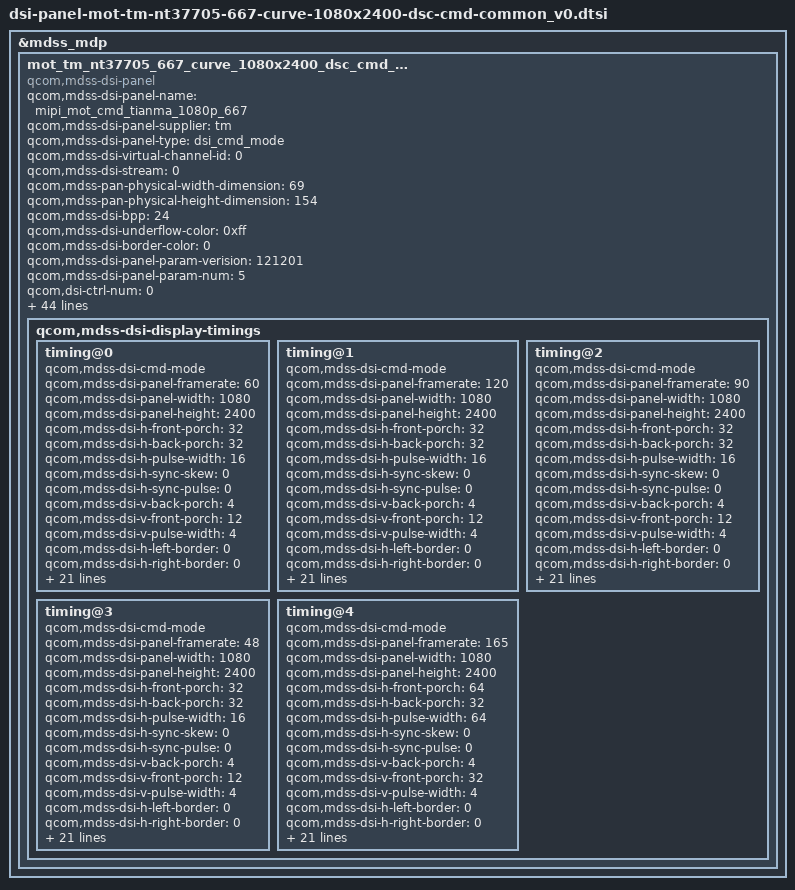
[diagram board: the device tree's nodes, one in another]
/* Copyright (c) 2019-2020, The Linux Foundation. All rights reserved.
 *
 * This program is free software; you can redistribute it and/or modify
 * it under the terms of the GNU General Public License version 2 and
 * only version 2 as published by the Free Software Foundation.
 *
 * This program is distributed in the hope that it will be useful,
 * but WITHOUT ANY WARRANTY; without even the implied warranty of
 * MERCHANTABILITY or FITNESS FOR A PARTICULAR PURPOSE.  See the
 * GNU General Public License for more details.
 */
#include "dsi-panel-mot-tm-nt37705-667-curve-1080x2400-dsc-cmd-common_v0_lhbm.dtsi"
&mdss_mdp {
mot_tm_nt37705_667_curve_1080x2400_dsc_cmd_v0: qcom,mdss_dsi_mot_tm_nt37705_667_curve_1080x2400_dsc_cmd_v0 {
compatible = "qcom,mdss-dsi-panel";
qcom,mdss-dsi-panel-name = "mipi_mot_cmd_tianma_1080p_667";
qcom,mdss-dsi-panel-supplier = "tm";
qcom,mdss-dsi-panel-type = "dsi_cmd_mode";
qcom,mdss-dsi-virtual-channel-id = <0>;
qcom,mdss-dsi-stream = <0>;
qcom,mdss-pan-physical-width-dimension = <69>;
qcom,mdss-pan-physical-height-dimension = <154>;
qcom,mdss-dsi-bpp = <24>;
qcom,mdss-dsi-underflow-color = <0xff>;
qcom,mdss-dsi-border-color = <0>;
qcom,mdss-dsi-panel-param-verision = <121201>;
qcom,mdss-dsi-panel-param-num = <5>;

qcom,dsi-ctrl-num = <0>;
qcom,dsi-phy-num = <0>;

qcom,mdss-dsi-traffic-mode = "burst_mode";
qcom,mdss-dsi-bllp-eof-power-mode;
qcom,mdss-dsi-bllp-power-mode;
qcom,mdss-dsi-lane-0-state;
qcom,mdss-dsi-lane-1-state;
qcom,mdss-dsi-lane-2-state;
qcom,mdss-dsi-lane-3-state;

qcom,mdss-dsi-dma-trigger = "trigger_sw";
qcom,mdss-dsi-mdp-trigger = "none";
qcom,mdss-dsi-reset-sequence = <0 12>, <1 1>, <0 1>, <1 13>;
qcom,mdss-dsi-lp11-init;
qcom,mdss-dsi-tx-eot-append;
qcom,mdss-dsi-te-pin-select = <1>;
qcom,mdss-dsi-te-dcs-command = <1>;
qcom,mdss-dsi-te-using-te-pin;

//qcom,bklt-dcs-2bytes-enabled;
qcom,mdss-dsi-bl-min-level = <4>;
qcom,mdss-dsi-bl-max-level = <14056>;
qcom,mdss-dsi-bl-pmic-control-type = "bl_ctrl_dcs";

qcom,mdss-dsi-panel-hdr-enabled;
qcom,mdss-dsi-panel-hdr-color-primaries = <14500 15500 32000
	        17000 15500 30000 8000 3000>;
qcom,mdss-dsi-panel-peak-brightness = <4200000>;

qcom,mdss-dsi-panel-blackness-level = <3230>;

qcom,mdss-dsi-dc-off-command = [
		39 00 00 00 00 00 06 F0 55 AA 52 08 00
		39 00 00 40 00 00 02 B2 01
		39 00 00 40 00 00 02 6F 02
		39 00 00 40 00 00 03 B2 3F 00
		39 00 00 40 00 00 1F B3 00 01 01 59 01 59 01 EA 01 EA 02 95 02 95 03 4D 03 4D 04 25 04 25 05 3C 05 3C 06 8A 06 8A
		39 00 00 40 00 00 02 6F 1E
		39 00 00 40 00 00 0F B3 06 8F 06 8F 09 80 09 80 0D BA 0D BA 0F FF
		39 00 00 40 00 00 02 6F 11
		39 00 00 40 00 00 04 B2 05 05 04
		39 00 00 40 00 00 06 F0 55 AA 52 08 01
		39 00 00 40 00 00 02 6F 05
		39 00 00 40 00 00 18 BB 44 44 44 44 44 44 44 44 44 44 44 44 44 44 44 44 40 40 40 40 40 40 4A
		39 00 00 00 00 00 06 F0 55 AA 52 08 02
		39 00 00 00 00 00 02 CC 10
		];

qcom,mdss-dsi-dc-off-command-state = "dsi_hs_mode";
qcom,mdss-dsi-dc-on-command = [
		39 00 00 00 00 00 06 F0 55 AA 52 08 00
		39 00 00 40 00 00 02 B2 80
		39 00 00 40 00 00 02 6F 02
		39 00 00 40 00 00 03 B2 FF 8F
		39 00 00 40 00 00 1F B3 00 00 00 00 00 00 00 00 00 00 00 00 00 00 00 00 00 00 00 00 00 00 00 00 00 00 00 00 00 00
		39 00 00 40 00 00 02 6F 1E
		39 00 00 40 00 00 0F B3 06 8F 06 8F 09 80 09 80 0D BA 0D BA 0F FF
		39 00 00 40 00 00 02 6F 11
		39 00 00 40 00 00 04 B2 00 00 00
		39 00 00 40 00 00 06 F0 55 AA 52 08 01
		39 00 00 40 00 00 02 6F 05
		39 00 00 40 00 00 18 BB 44 44 44 44 44 44 44 44 44 44 44 44 44 44 44 42 40 40 40 40 40 40 4A
		39 00 00 00 00 00 06 F0 55 AA 52 08 02
		39 00 00 00 00 00 02 CC 10
		];
qcom,mdss-dsi-dc-on-command-state = "dsi_hs_mode";

qcom,mdss-dsi-hbm-on-command = [
		39 00 00 00 00 00 03 51 3F FC
		39 00 00 00 00 00 02 87 00];

qcom,mdss-dsi-hbm-off-command = [
		39 00 00 00 00 00 02 87 00];

qcom,mdss-dsi-hbm-fod;
qcom,mdss-dsi-hbm-fod-on-command = [
		39 00 00 40 00 00 02 6F 01
		39 00 00 40 00 00 03 87 0F FF
		39 00 00 00 00 00 02 87 25];

qcom,mdss-dsi-panel-local-hbm-enabled;
qcom,mdss-dsi-panel-local-hbm-alpha-register = <0x87>;
qcom,mdss-dsi-panel-local-hbm-alpha-size = <4096>;

qcom,mdss-dsi-display-timings {
	timing@0{
		qcom,mdss-dsi-cmd-mode;
		qcom,mdss-dsi-panel-framerate = <60>;
		qcom,mdss-dsi-panel-width = <1080>;
		qcom,mdss-dsi-panel-height = <2400>;
		qcom,mdss-dsi-h-front-porch = <32>;
		qcom,mdss-dsi-h-back-porch = <32>;
		qcom,mdss-dsi-h-pulse-width = <16>;
		qcom,mdss-dsi-h-sync-skew = <0>;
		qcom,mdss-dsi-h-sync-pulse = <0>;
		qcom,mdss-dsi-v-back-porch = <4>;
		qcom,mdss-dsi-v-front-porch = <12>;
		qcom,mdss-dsi-v-pulse-width = <4>;
		qcom,mdss-dsi-h-left-border = <0>;
		qcom,mdss-dsi-h-right-border = <0>;
		qcom,mdss-dsi-v-top-border = <0>;
		qcom,mdss-dsi-v-bottom-border = <0>;
		qcom,mdss-mdp-transfer-time-us = <5500>;
		qcom,mdss-dsi-timing-switch-command = [
			15 01 00 00 10 00 02 2F 02 //03:48Hz 02:60Hz 01:90Hz 00:120Hz 04:165HZ
		];
		qcom,mdss-dsi-on-command = [
                        39 01 00 00 00 00 06 F0 55 AA 52 08 01
     			39 01 00 00 00 00 02 6F 05
			39 01 00 00 00 00 05 C5 15 15 15 DD
			39 01 00 00 00 00 02 6F 02
			39 01 00 00 00 00 03 C7 00 00
			39 01 00 00 00 00 06 F0 55 AA 52 08 07
			39 01 00 00 00 00 16 C4 36 00 05 F1 02 11 07 02 00 01 97 9C 3F FD FD 20 00 00 02 04 F1
			39 01 00 00 00 00 05 FF AA 55 A5 80
			39 01 00 00 00 00 02 6F 1A
			39 01 00 00 00 00 02 F4 55
			39 01 00 00 00 00 02 6F 15
			39 01 00 00 00 00 03 F8 01 5C
			39 01 00 00 00 00 02 6F 31
			39 01 00 00 00 00 03 F8 01 07
			39 01 00 00 00 00 02 6F 01
			39 01 00 00 00 00 02 1F 06
			39 01 00 00 00 00 02 6F 0F
			39 01 00 00 00 00 02 FC 00
			39 01 00 00 00 00 02 6F 09
			39 01 00 00 00 00 03 FC FC F0
			39 01 00 00 00 00 05 FF AA 55 A5 81
			39 01 00 00 00 00 02 6F 0E
			39 01 00 00 00 00 02 F5 00
			39 01 00 00 00 00 02 6F 19
			39 01 00 00 00 00 02 FB 00
			39 01 00 00 00 00 02 6F 05
			39 01 00 00 00 00 02 FE 3C
			39 01 00 00 00 00 02 6F 1E
			39 01 00 00 00 00 02 FB 0F
			39 01 00 00 00 00 05 FF AA 55 A5 83
			39 01 00 00 00 00 02 6F 12
			39 01 00 00 00 00 02 FE 41
			39 01 00 00 00 00 02 17 10
			39 01 00 00 00 00 02 26 00
			39 01 00 00 00 00 05 2A 00 00 04 37
			39 01 00 00 00 00 05 2B 00 00 09 5F
			39 01 00 00 00 00 02 2F 02
			39 01 00 00 00 00 02 35 00
			39 01 00 00 00 00 03 51 00 00
			39 01 00 00 00 00 02 53 20
			39 01 00 00 00 00 0A 88 01 02 1C 08 5E 00 00 00 00
			39 01 00 00 00 00 02 6F 01
			39 01 00 00 00 00 03 87 0F FF
			39 01 00 00 00 00 03 90 03 03
			39 01 00 00 00 00 13 91 AB 28 00 0C D2 00 02 25 01 14 00 07 09 75 08 7A 10 F0
			39 01 00 00 00 00 03 C7 00 00
			39 01 00 00 00 00 02 26 00
			39 01 00 00 00 00 02 1F 40
			39 01 00 00 00 00 05 FF AA 55 A5 81
                        39 01 00 00 00 00 02 6F 1E
                        39 01 00 00 00 00 02 FB 0F
                        39 01 00 00 00 00 06 F0 55 AA 52 08 00
                        39 01 00 00 00 00 03 B2 01 60
			05 01 00 00 64 00 01 11
			05 01 00 00 00 00 01 29];	/* display on */
		qcom,mdss-dsi-off-command = [
			05 01 00 00 00 00 01 28		/* display_off */
			05 01 00 00 78 00 01 10];	/* enter sleep mode */

		qcom,mdss-dsi-on-command-state = "dsi_lp_mode";
		qcom,mdss-dsi-off-command-state = "dsi_lp_mode";
		qcom,mdss-dsi-timing-switch-command-state =
			"dsi_lp_mode";
		qcom,compression-mode = "dsc";
		/* Why QCOM doesn't use this, even it used 2 encoder
		 * as for that dsi_sw43404_amoled_cmd, for ex */
		/* qcom,mdss-dsc-encoders = <2>; */
		qcom,mdss-dsc-version = <0x11>;
		qcom,mdss-dsc-slice-height = <12>;
		qcom,mdss-dsc-slice-width = <540>;
		qcom,mdss-dsc-slice-per-pkt = <1>;
		qcom,mdss-dsc-bit-per-component = <10>;
		qcom,mdss-dsc-bit-per-pixel = <8>;
		qcom,mdss-dsc-block-prediction-enable;
	};

	timing@1{
		qcom,mdss-dsi-cmd-mode;
		qcom,mdss-dsi-panel-framerate = <120>;
		qcom,mdss-dsi-panel-width = <1080>;
		qcom,mdss-dsi-panel-height = <2400>;
		qcom,mdss-dsi-h-front-porch = <32>;
		qcom,mdss-dsi-h-back-porch = <32>;
		qcom,mdss-dsi-h-pulse-width = <16>;
		qcom,mdss-dsi-h-sync-skew = <0>;
		qcom,mdss-dsi-h-sync-pulse = <0>;
		qcom,mdss-dsi-v-back-porch = <4>;
		qcom,mdss-dsi-v-front-porch = <12>;
		qcom,mdss-dsi-v-pulse-width = <4>;
		qcom,mdss-dsi-h-left-border = <0>;
		qcom,mdss-dsi-h-right-border = <0>;
		qcom,mdss-dsi-v-top-border = <0>;
		qcom,mdss-dsi-v-bottom-border = <0>;
		qcom,mdss-mdp-transfer-time-us = <5500>;
		qcom,mdss-dsi-timing-switch-command = [
			15 01 00 00 10 00 02 2F 00 //03:48Hz 02:60Hz 01:90Hz 00:120Hz 04:165HZ
		];
		qcom,mdss-dsi-on-command = [
                        39 01 00 00 00 00 06 F0 55 AA 52 08 01
     			39 01 00 00 00 00 02 6F 05
			39 01 00 00 00 00 05 C5 15 15 15 DD
			39 01 00 00 00 00 02 6F 02
			39 01 00 00 00 00 03 C7 00 00
			39 01 00 00 00 00 06 F0 55 AA 52 08 07
			39 01 00 00 00 00 16 C4 36 00 05 F1 02 11 07 02 00 01 97 9C 3F FD FD 20 00 00 02 04 F1
			39 01 00 00 00 00 05 FF AA 55 A5 80
			39 01 00 00 00 00 02 6F 1A
			39 01 00 00 00 00 02 F4 55
			39 01 00 00 00 00 02 6F 15
			39 01 00 00 00 00 03 F8 01 5C
			39 01 00 00 00 00 02 6F 31
			39 01 00 00 00 00 03 F8 01 07
			39 01 00 00 00 00 02 6F 01
			39 01 00 00 00 00 02 1F 06
			39 01 00 00 00 00 02 6F 0F
			39 01 00 00 00 00 02 FC 00
			39 01 00 00 00 00 02 6F 09
			39 01 00 00 00 00 03 FC FC F0
			39 01 00 00 00 00 05 FF AA 55 A5 81
			39 01 00 00 00 00 02 6F 0E
			39 01 00 00 00 00 02 F5 00
			39 01 00 00 00 00 02 6F 19
			39 01 00 00 00 00 02 FB 00
			39 01 00 00 00 00 02 6F 05
			39 01 00 00 00 00 02 FE 3C
			39 01 00 00 00 00 02 6F 1E
			39 01 00 00 00 00 02 FB 0F
			39 01 00 00 00 00 05 FF AA 55 A5 83
			39 01 00 00 00 00 02 6F 12
			39 01 00 00 00 00 02 FE 41
			39 01 00 00 00 00 02 17 10
			39 01 00 00 00 00 02 26 00
			39 01 00 00 00 00 05 2A 00 00 04 37
			39 01 00 00 00 00 05 2B 00 00 09 5F
			39 01 00 00 00 00 02 2F 00
			39 01 00 00 00 00 02 35 00
			39 01 00 00 00 00 03 51 00 00
			39 01 00 00 00 00 02 53 20
			39 01 00 00 00 00 0A 88 01 02 1C 08 5E 00 00 00 00
			39 01 00 00 00 00 02 6F 01
			39 01 00 00 00 00 03 87 0F FF
			39 01 00 00 00 00 03 90 03 03
			39 01 00 00 00 00 13 91 AB 28 00 0C D2 00 02 25 01 14 00 07 09 75 08 7A 10 F0
			39 01 00 00 00 00 03 C7 00 00
			39 01 00 00 00 00 02 26 00
			39 01 00 00 00 00 02 1F 40
			39 01 00 00 00 00 05 FF AA 55 A5 81
                        39 01 00 00 00 00 02 6F 1E
                        39 01 00 00 00 00 02 FB 0F
                        39 01 00 00 00 00 06 F0 55 AA 52 08 00
                        39 01 00 00 00 00 03 B2 01 60
			05 01 00 00 64 00 01 11
			05 01 00 00 00 00 01 29];	/* display on */
		qcom,mdss-dsi-off-command = [
			05 01 00 00 00 00 01 28		/* display_off */
			05 01 00 00 78 00 01 10];	/* enter sleep mode */

		qcom,mdss-dsi-on-command-state = "dsi_lp_mode";
		qcom,mdss-dsi-off-command-state = "dsi_lp_mode";
		qcom,mdss-dsi-timing-switch-command-state =
			"dsi_lp_mode";
		qcom,compression-mode = "dsc";
		/* Why QCOM doesn't use this, even it used 2 encoder
		 * as for that dsi_sw43404_amoled_cmd, for ex */
		/* qcom,mdss-dsc-encoders = <2>; */
		qcom,mdss-dsc-version = <0x11>;
		qcom,mdss-dsc-slice-height = <12>;
		qcom,mdss-dsc-slice-width = <540>;
		qcom,mdss-dsc-slice-per-pkt = <1>;
		qcom,mdss-dsc-bit-per-component = <10>;
		qcom,mdss-dsc-bit-per-pixel = <8>;
		qcom,mdss-dsc-block-prediction-enable;
	};
	timing@2{
		qcom,mdss-dsi-cmd-mode;
		qcom,mdss-dsi-panel-framerate = <90>;
		qcom,mdss-dsi-panel-width = <1080>;
		qcom,mdss-dsi-panel-height = <2400>;
		qcom,mdss-dsi-h-front-porch = <32>;
		qcom,mdss-dsi-h-back-porch = <32>;
		qcom,mdss-dsi-h-pulse-width = <16>;
		qcom,mdss-dsi-h-sync-skew = <0>;
		qcom,mdss-dsi-h-sync-pulse = <0>;
		qcom,mdss-dsi-v-back-porch = <4>;
		qcom,mdss-dsi-v-front-porch = <12>;
		qcom,mdss-dsi-v-pulse-width = <4>;
		qcom,mdss-dsi-h-left-border = <0>;
		qcom,mdss-dsi-h-right-border = <0>;
		qcom,mdss-dsi-v-top-border = <0>;
		qcom,mdss-dsi-v-bottom-border = <0>;
		qcom,mdss-mdp-transfer-time-us = <5500>;
		qcom,mdss-dsi-timing-switch-command = [
			15 01 00 00 10 00 02 2F 01 //03:48Hz 02:60Hz 01:90Hz 00:120Hz 04:165HZ
		];
		qcom,mdss-dsi-on-command = [
			39 01 00 00 00 00 06 F0 55 AA 52 08 00
			39 01 00 00 00 00 03 B2 01 60
                        39 01 00 00 00 00 06 F0 55 AA 52 08 01
     			39 01 00 00 00 00 02 6F 05
			39 01 00 00 00 00 05 C5 15 15 15 DD
			39 01 00 00 00 00 02 6F 02
			39 01 00 00 00 00 03 C7 00 00
			39 01 00 00 00 00 06 F0 55 AA 52 08 07
			39 01 00 00 00 00 16 C4 36 00 05 F1 02 11 07 02 00 01 97 9C 3F FD FD 20 00 00 02 04 F1
			39 01 00 00 00 00 05 FF AA 55 A5 80
			39 01 00 00 00 00 02 6F 1A
			39 01 00 00 00 00 02 F4 55
			39 01 00 00 00 00 02 6F 15
			39 01 00 00 00 00 03 F8 01 5C
			39 01 00 00 00 00 02 6F 31
			39 01 00 00 00 00 03 F8 01 07
			39 01 00 00 00 00 02 6F 01
			39 01 00 00 00 00 02 1F 06
			39 01 00 00 00 00 02 6F 0F
			39 01 00 00 00 00 02 FC 00
			39 01 00 00 00 00 02 6F 09
			39 01 00 00 00 00 03 FC FC F0
			39 01 00 00 00 00 05 FF AA 55 A5 81
			39 01 00 00 00 00 02 6F 0E
			39 01 00 00 00 00 02 F5 00
			39 01 00 00 00 00 02 6F 19
			39 01 00 00 00 00 02 FB 00
			39 01 00 00 00 00 02 6F 05
			39 01 00 00 00 00 02 FE 3C
			39 01 00 00 00 00 02 6F 1E
			39 01 00 00 00 00 02 FB 0F
			39 01 00 00 00 00 05 FF AA 55 A5 83
			39 01 00 00 00 00 02 6F 12
			39 01 00 00 00 00 02 FE 41
			39 01 00 00 00 00 02 17 10
			39 01 00 00 00 00 02 26 00
			39 01 00 00 00 00 05 2A 00 00 04 37
			39 01 00 00 00 00 05 2B 00 00 09 5F
			39 01 00 00 00 00 02 2F 01
			39 01 00 00 00 00 02 35 00
			39 01 00 00 00 00 03 51 00 00
			39 01 00 00 00 00 02 53 20
			39 01 00 00 00 00 0A 88 01 02 1C 08 5E 00 00 00 00
			39 01 00 00 00 00 02 6F 01
			39 01 00 00 00 00 03 87 0F FF
			39 01 00 00 00 00 03 90 03 03
			39 01 00 00 00 00 13 91 AB 28 00 0C D2 00 02 25 01 14 00 07 09 75 08 7A 10 F0
			39 01 00 00 00 00 03 C7 00 00
			39 01 00 00 00 00 02 26 00
			39 01 00 00 00 00 02 1F 40
			39 01 00 00 00 00 05 FF AA 55 A5 81
                        39 01 00 00 00 00 02 6F 1E
                        39 01 00 00 00 00 02 FB 0F
                        39 01 00 00 00 00 06 F0 55 AA 52 08 00
                        39 01 00 00 00 00 03 B2 01 60
			05 01 00 00 64 00 01 11
			05 01 00 00 00 00 01 29];	/* display on */
		qcom,mdss-dsi-off-command = [
			05 01 00 00 00 00 01 28		/* display_off */
			05 01 00 00 78 00 01 10];	/* enter sleep mode */

		qcom,mdss-dsi-on-command-state = "dsi_lp_mode";
		qcom,mdss-dsi-off-command-state = "dsi_lp_mode";
		qcom,mdss-dsi-timing-switch-command-state =
			"dsi_lp_mode";
		qcom,compression-mode = "dsc";
		/* Why QCOM doesn't use this, even it used 2 encoder
		 * as for that dsi_sw43404_amoled_cmd, for ex */
		/* qcom,mdss-dsc-encoders = <2>; */
		qcom,mdss-dsc-version = <0x11>;
		qcom,mdss-dsc-slice-height = <12>;
		qcom,mdss-dsc-slice-width = <540>;
		qcom,mdss-dsc-slice-per-pkt = <1>;
		qcom,mdss-dsc-bit-per-component = <10>;
		qcom,mdss-dsc-bit-per-pixel = <8>;
		qcom,mdss-dsc-block-prediction-enable;
	};
	timing@3{
		qcom,mdss-dsi-cmd-mode;
		qcom,mdss-dsi-panel-framerate = <48>;
		qcom,mdss-dsi-panel-width = <1080>;
		qcom,mdss-dsi-panel-height = <2400>;
		qcom,mdss-dsi-h-front-porch = <32>;
		qcom,mdss-dsi-h-back-porch = <32>;
		qcom,mdss-dsi-h-pulse-width = <16>;
		qcom,mdss-dsi-h-sync-skew = <0>;
		qcom,mdss-dsi-h-sync-pulse = <0>;
		qcom,mdss-dsi-v-back-porch = <4>;
		qcom,mdss-dsi-v-front-porch = <12>;
		qcom,mdss-dsi-v-pulse-width = <4>;
		qcom,mdss-dsi-h-left-border = <0>;
		qcom,mdss-dsi-h-right-border = <0>;
		qcom,mdss-dsi-v-top-border = <0>;
		qcom,mdss-dsi-v-bottom-border = <0>;
		qcom,mdss-mdp-transfer-time-us = <5500>;
		qcom,mdss-dsi-timing-switch-command = [
			15 01 00 00 10 00 02 2F 03 //03:48Hz 02:60Hz 01:90Hz 00:120Hz 04:165HZ
		];
		qcom,mdss-dsi-on-command = [
			39 01 00 00 00 00 06 F0 55 AA 52 08 00
			39 01 00 00 00 00 03 B2 01 60
                        39 01 00 00 00 00 06 F0 55 AA 52 08 01
     			39 01 00 00 00 00 02 6F 05
			39 01 00 00 00 00 05 C5 15 15 15 DD
			39 01 00 00 00 00 02 6F 02
			39 01 00 00 00 00 03 C7 00 00
			39 01 00 00 00 00 06 F0 55 AA 52 08 07
			39 01 00 00 00 00 16 C4 36 00 05 F1 02 11 07 02 00 01 97 9C 3F FD FD 20 00 00 02 04 F1
			39 01 00 00 00 00 05 FF AA 55 A5 80
			39 01 00 00 00 00 02 6F 1A
			39 01 00 00 00 00 02 F4 55
			39 01 00 00 00 00 02 6F 15
			39 01 00 00 00 00 03 F8 01 5C
			39 01 00 00 00 00 02 6F 31
			39 01 00 00 00 00 03 F8 01 07
			39 01 00 00 00 00 02 6F 01
			39 01 00 00 00 00 02 1F 06
			39 01 00 00 00 00 02 6F 0F
			39 01 00 00 00 00 02 FC 00
			39 01 00 00 00 00 02 6F 09
			39 01 00 00 00 00 03 FC FC F0
			39 01 00 00 00 00 05 FF AA 55 A5 81
			39 01 00 00 00 00 02 6F 0E
			39 01 00 00 00 00 02 F5 00
			39 01 00 00 00 00 02 6F 19
			39 01 00 00 00 00 02 FB 00
			39 01 00 00 00 00 02 6F 05
			39 01 00 00 00 00 02 FE 3C
			39 01 00 00 00 00 02 6F 1E
			39 01 00 00 00 00 02 FB 0F
			39 01 00 00 00 00 05 FF AA 55 A5 83
			39 01 00 00 00 00 02 6F 12
			39 01 00 00 00 00 02 FE 41
			39 01 00 00 00 00 02 17 10
			39 01 00 00 00 00 02 26 00
			39 01 00 00 00 00 05 2A 00 00 04 37
			39 01 00 00 00 00 05 2B 00 00 09 5F
			39 01 00 00 00 00 02 2F 03
			39 01 00 00 00 00 02 35 00
			39 01 00 00 00 00 03 51 00 00
			39 01 00 00 00 00 02 53 20
			39 01 00 00 00 00 0A 88 01 02 1C 08 5E 00 00 00 00
			39 01 00 00 00 00 02 6F 01
			39 01 00 00 00 00 03 87 0F FF
			39 01 00 00 00 00 03 90 03 03
			39 01 00 00 00 00 13 91 AB 28 00 0C D2 00 02 25 01 14 00 07 09 75 08 7A 10 F0
			39 01 00 00 00 00 03 C7 00 00
			39 01 00 00 00 00 02 26 00
			39 01 00 00 00 00 02 1F 40
			39 01 00 00 00 00 05 FF AA 55 A5 81
                        39 01 00 00 00 00 02 6F 1E
                        39 01 00 00 00 00 02 FB 0F
                        39 01 00 00 00 00 06 F0 55 AA 52 08 00
                        39 01 00 00 00 00 03 B2 01 60
			05 01 00 00 64 00 01 11
			05 01 00 00 00 00 01 29];	/* display on */
		qcom,mdss-dsi-off-command = [
			05 01 00 00 00 00 01 28		/* display_off */
			05 01 00 00 78 00 01 10];	/* enter sleep mode */

		qcom,mdss-dsi-on-command-state = "dsi_lp_mode";
		qcom,mdss-dsi-off-command-state = "dsi_lp_mode";
		qcom,mdss-dsi-timing-switch-command-state =
			"dsi_lp_mode";
		qcom,compression-mode = "dsc";
		/* Why QCOM doesn't use this, even it used 2 encoder
		 * as for that dsi_sw43404_amoled_cmd, for ex */
		/* qcom,mdss-dsc-encoders = <2>; */
		qcom,mdss-dsc-version = <0x11>;
		qcom,mdss-dsc-slice-height = <12>;
		qcom,mdss-dsc-slice-width = <540>;
		qcom,mdss-dsc-slice-per-pkt = <1>;
		qcom,mdss-dsc-bit-per-component = <10>;
		qcom,mdss-dsc-bit-per-pixel = <8>;
		qcom,mdss-dsc-block-prediction-enable;
	};
	timing@4{
		qcom,mdss-dsi-cmd-mode;
		qcom,mdss-dsi-panel-framerate = <165>;
		qcom,mdss-dsi-panel-width = <1080>;
		qcom,mdss-dsi-panel-height = <2400>;
		qcom,mdss-dsi-h-front-porch = <64>;
		qcom,mdss-dsi-h-back-porch = <32>;
		qcom,mdss-dsi-h-pulse-width = <64>;
		qcom,mdss-dsi-h-sync-skew = <0>;
		qcom,mdss-dsi-h-sync-pulse = <0>;
		qcom,mdss-dsi-v-back-porch = <4>;
		qcom,mdss-dsi-v-front-porch = <32>;
		qcom,mdss-dsi-v-pulse-width = <4>;
		qcom,mdss-dsi-h-left-border = <0>;
		qcom,mdss-dsi-h-right-border = <0>;
		qcom,mdss-dsi-v-top-border = <0>;
		qcom,mdss-dsi-v-bottom-border = <0>;
		qcom,mdss-mdp-transfer-time-us = <5500>;
		qcom,mdss-dsi-timing-switch-command = [
			15 01 00 00 10 00 02 2F 04 //03:48Hz 02:60Hz 01:90Hz 00:120Hz 04:165HZ
		];
		qcom,mdss-dsi-on-command = [
			39 01 00 00 00 00 06 F0 55 AA 52 08 00
			39 01 00 00 00 00 03 B2 01 60
                        39 01 00 00 00 00 06 F0 55 AA 52 08 01
     			39 01 00 00 00 00 02 6F 05
			39 01 00 00 00 00 05 C5 15 15 15 DD
			39 01 00 00 00 00 02 6F 02
			39 01 00 00 00 00 03 C7 00 00
			39 01 00 00 00 00 06 F0 55 AA 52 08 07
			39 01 00 00 00 00 16 C4 36 00 05 F1 02 11 07 02 00 01 97 9C 3F FD FD 20 00 00 02 04 F1
			39 01 00 00 00 00 05 FF AA 55 A5 80
			39 01 00 00 00 00 02 6F 1A
			39 01 00 00 00 00 02 F4 55
			39 01 00 00 00 00 02 6F 15
			39 01 00 00 00 00 03 F8 01 5C
			39 01 00 00 00 00 02 6F 31
			39 01 00 00 00 00 03 F8 01 07
			39 01 00 00 00 00 02 6F 01
			39 01 00 00 00 00 02 1F 06
			39 01 00 00 00 00 02 6F 0F
			39 01 00 00 00 00 02 FC 00
			39 01 00 00 00 00 02 6F 09
			39 01 00 00 00 00 03 FC FC F0
			39 01 00 00 00 00 05 FF AA 55 A5 81
			39 01 00 00 00 00 02 6F 0E
			39 01 00 00 00 00 02 F5 00
			39 01 00 00 00 00 02 6F 19
			39 01 00 00 00 00 02 FB 00
			39 01 00 00 00 00 02 6F 05
			39 01 00 00 00 00 02 FE 3C
			39 01 00 00 00 00 02 6F 1E
			39 01 00 00 00 00 02 FB 0F
			39 01 00 00 00 00 05 FF AA 55 A5 83
			39 01 00 00 00 00 02 6F 12
			39 01 00 00 00 00 02 FE 41
			39 01 00 00 00 00 02 17 10
			39 01 00 00 00 00 02 26 00
			39 01 00 00 00 00 05 2A 00 00 04 37
			39 01 00 00 00 00 05 2B 00 00 09 5F
			39 01 00 00 00 00 02 2F 04
			39 01 00 00 00 00 02 35 00
			39 01 00 00 00 00 03 51 00 00
			39 01 00 00 00 00 02 53 20
			39 01 00 00 00 00 0A 88 01 02 1C 08 5E 00 00 00 00
			39 01 00 00 00 00 02 6F 01
			39 01 00 00 00 00 03 87 0F FF
			39 01 00 00 00 00 03 90 03 03
			39 01 00 00 00 00 13 91 AB 28 00 0C D2 00 02 25 01 14 00 07 09 75 08 7A 10 F0
			39 01 00 00 00 00 03 C7 00 00
			39 01 00 00 00 00 02 26 00
			39 01 00 00 00 00 02 1F 40
			39 01 00 00 00 00 05 FF AA 55 A5 81
                        39 01 00 00 00 00 02 6F 1E
                        39 01 00 00 00 00 02 FB 0F
                        39 01 00 00 00 00 06 F0 55 AA 52 08 00
                        39 01 00 00 00 00 03 B2 01 60
			05 01 00 00 64 00 01 11
			05 01 00 00 00 00 01 29];	/* display on */
		qcom,mdss-dsi-off-command = [
			05 01 00 00 00 00 01 28		/* display_off */
			05 01 00 00 78 00 01 10];	/* enter sleep mode */

		qcom,mdss-dsi-on-command-state = "dsi_lp_mode";
		qcom,mdss-dsi-off-command-state = "dsi_lp_mode";
		qcom,mdss-dsi-timing-switch-command-state =
			"dsi_lp_mode";
		qcom,compression-mode = "dsc";
		/* Why QCOM doesn't use this, even it used 2 encoder
		 * as for that dsi_sw43404_amoled_cmd, for ex */
		/* qcom,mdss-dsc-encoders = <2>; */
		qcom,mdss-dsc-version = <0x11>;
		qcom,mdss-dsc-slice-height = <12>;
		qcom,mdss-dsc-slice-width = <540>;
		qcom,mdss-dsc-slice-per-pkt = <1>;
		qcom,mdss-dsc-bit-per-component = <10>;
		qcom,mdss-dsc-bit-per-pixel = <8>;
		qcom,mdss-dsc-block-prediction-enable;
	};
};

};

};
